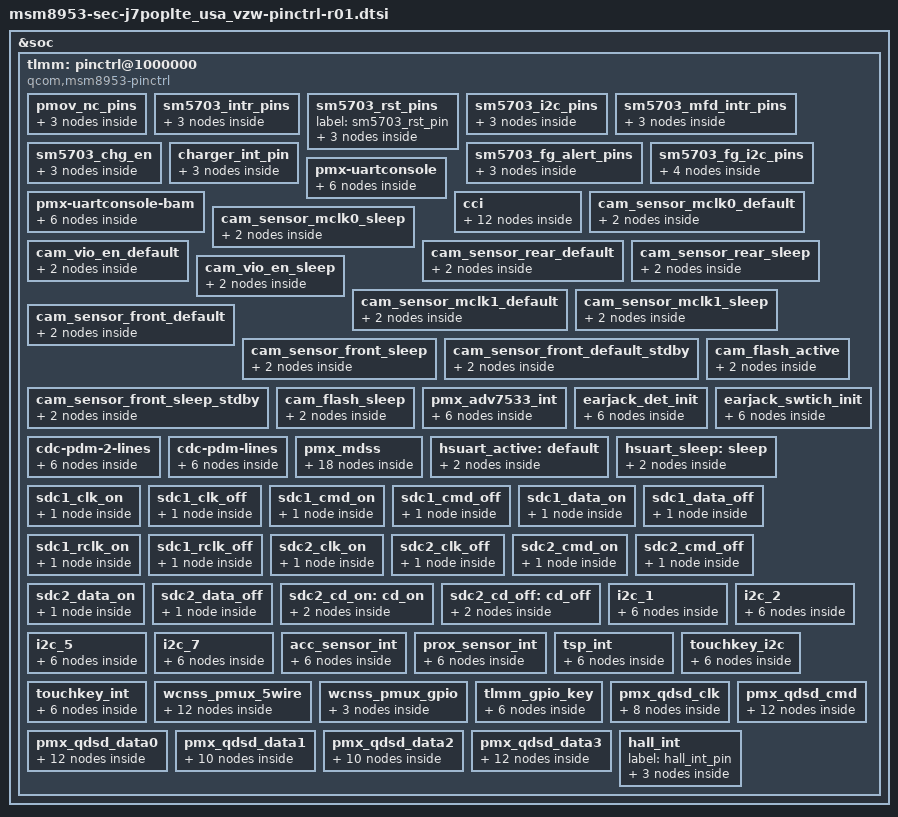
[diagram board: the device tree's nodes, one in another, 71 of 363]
/*
 * Copyright (c) 2015-2016, The Linux Foundation. All rights reserved.
 *
 * This program is free software; you can redistribute it and/or modify
 * it under the terms of the GNU General Public License version 2 and
 * only version 2 as published by the Free Software Foundation.
 *
 * This program is distributed in the hope that it will be useful,
 * but WITHOUT ANY WARRANTY; without even the implied warranty of
 * MERCHANTABILITY or FITNESS FOR A PARTICULAR PURPOSE.  See the
 * GNU General Public License for more details.
 */

&soc {
	tlmm: pinctrl@1000000 {
		compatible = "qcom,msm8953-pinctrl";
		reg = <0x1000000 0x300000>;
		interrupts = <0 208 0>;
		gpio-controller;
		#gpio-cells = <2>;
		interrupt-controller;
		#interrupt-cells = <2>;

		pmov_nc_pins {
			label = "pmov_nc_pins";
			qcom,num-grp-pins = <1>;
			qcom,pin-func = <0>;
			nc_gpio_default: default {
				mux {
					pins = "gpio33", "gpio96";
					function ="gpio";
				};
				config {
					pins = "gpio33", "gpio96";
					drive-strength = <2>; /* 2mA */
					bias-pull-down;
					input-enable;
				};
			};
		};

		sm5703_intr_pins {
			qcom,pin-func = <0>;
			label = "sm5703_gpio_int";
			sm5703_interrupt_default: default {
				mux {
					pins = "gpio63";
					function = "gpio";
				};
				config {
					pins = "gpio63";
					drive-strength = <2>;
					bias-disable;
				};
			};
		};

		sm5703_rst_pins {
			label = "sm5703_rst_pin";
			sm5703_rst_default: default {
				mux {
					pins = "gpio87";
					function = "gpio";
				};
				config {
					pins = "gpio87";
					drive-strength = <2>;
					bias-disable;
					output-high;
				};
			};
		};

		sm5703_i2c_pins {
			sm5703_i2c_default: default {
				mux {
					pins = "gpio98", "gpio99"; /* SDA, SCL */
                        		function = "gpio";
				};
				config {
					pins = "gpio98", "gpio99";
					drive-strength = <2>;
					bias-disable;
				};
			};
		};

		sm5703_mfd_intr_pins {
			sm5703_mfd_interrupt_default: sm5703_mfd_interrupt_default {
				/*default state*/
				mux {
					pins = "gpio61";
					function = "gpio";
				};
				config {
					pins = "gpio61";
					drive-strength = <2>;
					bias-disable; /* No PULL */
				};
			};
		};

		/* Chg_en pin */
		sm5703_chg_en {
			sm5703_chg_en_default: sm5703_chg_en_default {
				/*default state*/
				mux {
					pins = "gpio128";
					function = "gpio";
				};
				config {
					pins = "gpio128";
					drive-strength = <2>;
					bias-disable;
					output-low;
				};
			};
		};

		charger_int_pin {
			qcom,num-grp-pins = <1>;
			qcom,pin-func = <0>;
			label = "charger_int_gpio";
			charger_int_active: charger_int_active {
				mux {
					pins = "gpio61";
					function = "gpio";
				};
				config {
					pins = "gpio61";
					drive-strength = <2>;
					bias-disable;         /* No PULL */
				};
			};
		};

		/* Fuelgauge alert pin */
                sm5703_fg_alert_pins {
			qcom,num-grp-pins = <1>;
			qcom,pin-func = <0>;
			label = "fuel_int_gpio";
			fuel_int_active: fuel_int_active {
				mux {
					pins = "gpio62";
					function = "gpio";
				};
				config {
					pins = "gpio62";
					drive-strength = <2>;
					bias-disable;         /* No PULL */
					input-enable;
				};
			};
		};

		/* Fuelgauge I2C pins */
		sm5703_fg_i2c_pins {
			qcom,num-grp-pins = <2>;
			qcom,pin-func = <0>;
			label = "fg_i2c";

			fg_i2c_active: fg_i2c_active {
				mux {
					pins = "gpio38", "gpio39";
					function = "gpio";
				};
				config {
					pins = "gpio38", "gpio39";
					drive-strength = <2>;	/* 2 MA */
					bias-disable; /* No PULL */
				};
			};

			fg_i2c_sleep: fg_i2c_sleep {
				drive-strength = <2>;	/* 2 MA */
				bias-disable; /* No PULL */
			};
		};

		pmx-uartconsole {
			uart_console_active: uart_console_active {
				mux {
					pins = "gpio4", "gpio5";
					function = "blsp_uart2";
				};

				config {
					pins = "gpio4", "gpio5";
					drive-strength = <2>;
					bias-pull-down;
				};
			};

			uart_console_sleep: uart_console_sleep {
				mux {
					pins = "gpio4", "gpio5";
					function = "blsp_uart2";
				};

				config {
					pins = "gpio4", "gpio5";
					drive-strength = <2>;
					bias-pull-down;
				};
			};

		};

		pmx-uartconsole-bam {
			uart_console_bam_active: uart_console_bam_active {
				mux {
					pins = "gpio4", "gpio5";
					function = "blsp_uart2";
				};

				config {
					pins = "gpio4", "gpio5";
					drive-strength = <16>;
					bias-disable;
				};
			};

			uart_console_bam_sleep: uart_console_bam_sleep {
				mux {
					pins = "gpio4", "gpio5";
					function = "blsp_uart2";
				};

				config {
					pins = "gpio4", "gpio5";
					drive-strength = <2>;
					bias-disable;
				};
			};

		};

		cci {
			cci0_active: cci0_active {
				/* cci0 active state */
				mux {
					/* CLK, DATA */
					pins = "gpio29", "gpio30";
					function = "cci_i2c";
				};

				config {
					pins = "gpio29", "gpio30";
					drive-strength = <2>; /* 2 MA */
					bias-disable; /* No PULL */
				};
			};

			cci0_suspend: cci0_suspend {
				/* cci0 suspended state */
				mux {
					/* CLK, DATA */
					pins = "gpio29", "gpio30";
					function = "gpio";
				};

				config {
					pins = "gpio29", "gpio30";
					drive-strength = <2>; /* 2 MA */
					bias-disable; /* No PULL */
				};
			};

			cci1_active: cci1_active {
				/* cci1 active state */
				mux {
					/* CLK, DATA */
					pins = "gpio31", "gpio32";
					function = "cci_i2c";
				};

				config {
					pins = "gpio31", "gpio32";
					drive-strength = <2>; /* 2 MA */
					bias-disable; /* No PULL */
				};
			};

			cci1_suspend: cci1_suspend {
				/* cci1 suspended state */
				mux {
					/* CLK, DATA */
					pins = "gpio31", "gpio32";
					function = "gpio";
				};

				config {
					pins = "gpio31", "gpio32";
					drive-strength = <2>; /* 2 MA */
					bias-disable; /* No PULL */
				};
			};
		};

		/*sensors */
		cam_sensor_mclk0_default: cam_sensor_mclk0_default {
			/* MCLK0 */
			mux {
				/* CLK, DATA */
				pins = "gpio26";
				function = "cam_mclk";
			};

			config {
				pins = "gpio26";
				bias-disable; /* No PULL */
				drive-strength = <4>; /* 4 MA */
			};
		};

		cam_sensor_mclk0_sleep: cam_sensor_mclk0_sleep {
			/* MCLK0 */
			mux {
				/* CLK, DATA */
				pins = "gpio26";
				function = "gpio";
			};

			config {
				pins = "gpio26";
				bias-pull-down; /* PULL DOWN */
				drive-strength = <4>; /* 4 MA */
				output-low;
			};
		};

		cam_sensor_rear_default: cam_sensor_rear_default {
			/* RESET */
			mux {
				pins = "gpio40";
				function = "gpio";
			};

			config {
				pins = "gpio40";
				bias-pull-down; /* PULL DOWN */
				drive-strength = <2>; /* 2 MA */
				output-low;
			};
		};

		cam_sensor_rear_sleep: cam_sensor_rear_sleep {
			/* RESET */
			mux {
				pins = "gpio40";
				function = "gpio";
			};

			config {
				pins = "gpio40";
				bias-pull-down; /* PULL DOWN */
				drive-strength = <2>; /* 2 MA */
			};
		};

		cam_vio_en_default: cam_vio_en_default {
			/* VIO */
			mux {
				pins = "gpio134";
				function = "gpio";
			};

			config {
				pins = "gpio134";
				bias-pull-down; /* PULL DOWN */
				drive-strength = <2>; /* 2 MA */
				output-low;
			};
		};

		cam_vio_en_sleep: cam_vio_en_sleep {
			/* VDIO */
			mux {
				pins = "gpio134";
				function = "gpio";
			};

			config {
				pins = "gpio134";
				bias-pull-down; /* PULL DOWN */
				drive-strength = <2>; /* 2 MA */
				output-low;
			};
		};

		cam_sensor_mclk1_default: cam_sensor_mclk1_default {
			/* MCLK1 */
			mux {
				/* CLK, DATA */
				pins = "gpio27";
				function = "cam_mclk";
			};

			config {
				pins = "gpio27";
				bias-disable; /* No PULL */
				drive-strength = <4>; /* 4 MA */
			};
		};

		cam_sensor_mclk1_sleep: cam_sensor_mclk1_sleep {
			/* MCLK1 */
			mux {
				/* CLK, DATA */
				pins = "gpio27";
				function = "gpio";
			};

			config {
				pins = "gpio27";
				bias-pull-down; /* PULL DOWN */
				drive-strength = <4>; /* 4 MA */
				output-low;
			};
		};

		cam_sensor_front_default: cam_sensor_front_default {
			/* RESET*/
			mux {
				pins = "gpio129";
				function = "gpio";
			};

			config {
				pins = "gpio129";
				bias-pull-down; /* PULL DOWN */
				output-low;
				drive-strength = <2>; /* 2 MA */
			};
		};

		cam_sensor_front_sleep: cam_sensor_front_sleep {
			/* RESET */
			mux {
				pins = "gpio129";
				function = "gpio";
			};

			config {
				pins = "gpio129";
				bias-disable; /* No PULL */
				drive-strength = <2>; /* 2 MA */
			};
		};

		cam_sensor_front_default_stdby: cam_sensor_front_default_stdby {
			/* STDBY */
			mux {
				pins = "gpio97";
				function = "gpio";
			};

			config {
				pins = "gpio97";
				bias-pull-down; /* PULL DOWN */
				output-low;
				drive-strength = <2>; /* 2 MA */
			};
		};

		cam_sensor_front_sleep_stdby: cam_sensor_front_sleep_stdby {
			/* STDBY */
			mux {
				pins = "gpio97";
				function = "gpio";
			};

			config {
				pins = "gpio97";
				bias-disable; /* No PULL */
				drive-strength = <2>; /* 2 MA */
			};
		};

		cam_flash_active: cam_flash_active {
			/* TORCH, FLASH */
			mux {
				pins = "gpio34", "gpio36";
				function = "gpio";
			};

			config {
				pins = "gpio34", "gpio36";
				bias-pull-down; /* PULL DOWN */
				drive-strength = <2>; /* 2 MA */
				output-low;
			};
		};

		cam_flash_sleep: cam_flash_sleep {
			/* TORCH, FLASH */
			mux {
				pins = "gpio34", "gpio36";
				function = "gpio";
			};

			config {
				pins = "gpio34", "gpio36";
				bias-pull-down; /* PULL DOWN */
				drive-strength = <2>; /* 2 MA */
				output-low;
			};
		};

		pmx_adv7533_int: pmx_adv7533_int {
			adv7533_int_active: adv7533_int_active {
				mux {
					pins = "gpio90";
					function = "gpio";
				};

				config {
					pins = "gpio90";
					drive-strength = <16>;
					bias-disable;
				};
			};

			adv7533_int_suspend: adv7533_int_suspend {
				mux {
					pins = "gpio90";
					function = "gpio";
				};

				config {
					pins = "gpio90";
					drive-strength = <16>;
					bias-disable;
				};
			};

		};

		/* ear jack */
		earjack_det_init: earjack_det_init {
			earjack_det_act: earjack_det_act {
				mux {
					pins = "gpio48";
					function = "gpio";
				};
				config {
					pins = "gpio48";
					drive-strength = <2>;
					bias-disable;
				};
			};
			earjack_det_sus: earjack_det_sus {
				mux {
					pins = "gpio48";
					function = "gpio";
				};
				config {
					pins = "gpio48";
					drive-strength = <2>;
					bias-disable;
				};
			};
		};

		earjack_swtich_init: earjack_swtich_init {
			earjack_switch_act: earjack_switch_act {
				mux {
					pins = "gpio141";
					function = "gpio";
				};
				config {
					pins = "gpio141";
					drive-strength = <2>;
					bias-disable;
				};
			};
			earjack_switch_sus: earjack_switch_sus {
				mux {
					pins = "gpio141";
					function = "gpio";
				};
				config {
					pins = "gpio141";
					drive-strength = <2>;
					bias-disable;
				};
			};
		};

		cdc-pdm-2-lines {
			cdc_pdm_lines_2_act: pdm_lines_2_on {
				mux {
					pins = "gpio70", "gpio71", "gpio72";
					function = "cdc_pdm0";
				};

				config {
					pins = "gpio70", "gpio71", "gpio72";
					drive-strength = <2>;
				};
			};

			cdc_pdm_lines_2_sus: pdm_lines_2_off {
				mux {
					pins = "gpio70", "gpio71", "gpio72";
					function = "cdc_pdm0";
				};

				config {
					pins = "gpio70", "gpio71", "gpio72";
					drive-strength = <2>;
					bias-disable;
				};
			};
		};

		cdc-pdm-lines {
			cdc_pdm_lines_act: pdm_lines_on {
				mux {
					pins = "gpio69", "gpio73", "gpio74";
					function = "cdc_pdm0";
				};

				config {
					pins = "gpio69", "gpio73", "gpio74";
					drive-strength = <2>;
				};
			};
			cdc_pdm_lines_sus: pdm_lines_off {
				mux {
					pins = "gpio69", "gpio73", "gpio74";
					function = "cdc_pdm0";
				};

				config {
					pins = "gpio69", "gpio73", "gpio74";
					drive-strength = <2>;
					bias-disable;
				};
			};
		};

		pmx_mdss: pmx_mdss {
			mdss_dsi_active: mdss_dsi_active {
				mux {
					pins =
						/* LCD */
						"gpio50", "gpio94",
						/* BLIC */
						"gpio41", "gpio22", "gpio23";

					function = "gpio";
				};

				config {
					pins =
						/* LCD */
						"gpio50", "gpio94",
						/* BLIC */
						"gpio41", "gpio22", "gpio23";

					drive-strength = <8>; /* 8 mA */
					bias-pull-down;
				};
			};

			mdss_dsi_suspend: mdss_dsi_suspend {
				mux {
					pins =
						/* LCD */
						"gpio50", "gpio94",
						/* BLIC */
						"gpio41", "gpio22", "gpio23";

					function = "gpio";
				};

				config {
					pins =
						/* LCD */
						"gpio50", "gpio94",
						/* BLIC */
						"gpio41", "gpio22", "gpio23";

					drive-strength = <2>; /* 2 mA */
					bias-pull-down; /* pull down */
				};
			};

			mdss_dsi_esd_active: mdss_dsi_esd_active {
				mux {
					pins =
						/* ESD */
						"gpio13";

					function = "gpio";
				};

				config {
					pins =
						/* ESD */
						"gpio13";

					drive-strength = <8>; /* 8 mA */
					bias-disable;         /* No PULL */
					input-enable;
				};
			};

			mdss_dsi_esd_suspend: mdss_dsi_esd_suspend {
				mux {
					pins =
						/* ESD */
						"gpio13";

					function = "gpio";
				};

				config {
					pins =
						/* ESD */
						"gpio13";

					drive-strength = <2>; /* 2 mA */
					bias-disable;         /* No PULL */
					input-enable;
				};
			};
			mdss_dsi_blic_active: mdss_dsi_blic_active {
				mux {
					pins =
						/* BLIC I2C */
						"gpio14", "gpio15";

					function = "gpio";
				};

				config {
					pins =
						/* BLIC I2C */
						"gpio14", "gpio15";

					drive-strength = <8>; /* 8 mA */
					bias-disable;         /* No PULL */
					input-enable;
				};
			};

			mdss_dsi_blic_suspend: mdss_dsi_blic_suspend {
				mux {
					pins =
						/* BLIC I2C */
						"gpio14", "gpio15";

					function = "gpio";
				};

				config {
					pins =
						/* BLIC I2C */
						"gpio14", "gpio15";

					drive-strength = <2>; /* 2 mA */
					bias-disable;         /* No PULL */
					input-enable;
				};
			};


		};

		hsuart_active: default {
			mux {
				pins = "gpio14", "gpio15";
				function = "blsp_uart4";
			};

			config {
				pins = "gpio14", "gpio15";
				drive-strength = <16>;
				bias-disable;
			};
		};

		hsuart_sleep: sleep {
			mux {
				pins = "gpio14", "gpio15";
				function = "gpio";
			};

			config {
				pins = "gpio14", "gpio15";
				drive-strength = <2>;
				bias-disable;
			};
		};

		/* SDC pin type */
		sdc1_clk_on: sdc1_clk_on {
			config {
				pins = "sdc1_clk";
				bias-disable;		/* NO pull */
				drive-strength = <16>;	/* 16 MA */
			};
		};

		sdc1_clk_off: sdc1_clk_off {
			config {
				pins = "sdc1_clk";
				bias-disable;		/* NO pull */
				drive-strength = <2>;	/* 2 MA */
			};
		};

		sdc1_cmd_on: sdc1_cmd_on {
			config {
				pins = "sdc1_cmd";
				bias-pull-up;		/* pull up */
				drive-strength = <10>;	/* 10 MA */
			};
		};

		sdc1_cmd_off: sdc1_cmd_off {
			config {
				pins = "sdc1_cmd";
				num-grp-pins = <1>;
				bias-pull-up;		/* pull up */
				drive-strength = <2>;	/* 2 MA */
			};
		};

		sdc1_data_on: sdc1_data_on {
			config {
				pins = "sdc1_data";
				bias-pull-up;		/* pull up */
				drive-strength = <10>;	/* 10 MA */
			};
		};

		sdc1_data_off: sdc1_data_off {
			config {
				pins = "sdc1_data";
				bias-pull-up;		/* pull up */
				drive-strength = <2>;	/* 2 MA */
			};
		};

		sdc1_rclk_on: sdc1_rclk_on {
			config {
				pins = "sdc1_rclk";
				bias-pull-down; /* pull down */
			};
		};

		sdc1_rclk_off: sdc1_rclk_off {
			config {
				pins = "sdc1_rclk";
				bias-pull-down; /* pull down */
			};
		};

		sdc2_clk_on: sdc2_clk_on {
			config {
				pins = "sdc2_clk";
				drive-strength = <16>; /* 16 MA */
				bias-disable; /* NO pull */
			};
		};

		sdc2_clk_off: sdc2_clk_off {
			config {
				pins = "sdc2_clk";
				bias-disable; /* NO pull */
				drive-strength = <2>; /* 2 MA */
			};
		};

		sdc2_cmd_on: sdc2_cmd_on {
			config {
				pins = "sdc2_cmd";
				bias-pull-up; /* pull up */
				drive-strength = <8>; /* 8 MA */
			};
		};

		sdc2_cmd_off: sdc2_cmd_off {
			config {
				pins = "sdc2_cmd";
				bias-pull-up; /* pull up */
				drive-strength = <2>; /* 2 MA */
			};
		};

		sdc2_data_on: sdc2_data_on {
			config {
				pins = "sdc2_data";
				bias-pull-up; /* pull up */
				drive-strength = <8>; /* 8 MA */
			};
		};

		sdc2_data_off: sdc2_data_off {
			config {
				pins = "sdc2_data";
				bias-pull-up; /* pull up */
				drive-strength = <2>; /* 2 MA */
			};
		};

		sdc2_cd_on: cd_on {
			mux {
				pins = "gpio133";
				function = "gpio";
			};

			config {
				pins = "gpio133";
				drive-strength = <2>;
				bias-disable;
			};
		};

		sdc2_cd_off: cd_off {
			mux {
				pins = "gpio133";
				function = "gpio";
			};

			config {
				pins = "gpio133";
				drive-strength = <2>;
				bias-disable;
			};
		};

		i2c_1 {
			i2c_1_active: i2c_1_active {
				/* active state */
				mux {
					pins = "gpio2", "gpio3";
					function = "blsp_i2c1";
				};

				config {
					pins = "gpio2", "gpio3";
					drive-strength = <2>;
					bias-disable;
				};
			};

			i2c_1_sleep: i2c_1_sleep {
				/* suspended state */
				mux {
					pins = "gpio2", "gpio3";
					function = "gpio";
				};

				config {
					pins = "gpio2", "gpio3";
					drive-strength = <2>;
					bias-disable;
				};
			};
		};
		
		i2c_2 {
			i2c_2_active: i2c_2_active {
				/* active state */
				mux {
					pins = "gpio6", "gpio7";
					function = "blsp_i2c2";
				};

				config {
					pins = "gpio6", "gpio7";
					drive-strength = <2>;
					bias-disable;
				};
			};

			i2c_2_sleep: i2c_2_sleep {
				/* suspended state */
				mux {
					pins = "gpio6", "gpio7";
					function = "blsp_i2c2";
				};

				config {
					pins = "gpio6", "gpio7";
					drive-strength = <2>;
					bias-disable;
				};
			};
		};

		i2c_5 {
			i2c_5_active: i2c_5_active {
				/* active state */
				mux {
					pins = "gpio18", "gpio19";
					function = "blsp_i2c5";
				};

				config {
					pins = "gpio18", "gpio19";
					drive-strength = <2>;
					bias-disable;
				};
			};

			i2c_5_sleep: i2c_5_sleep {
				/* suspended state */
				mux {
					pins = "gpio18", "gpio19";
					function = "gpio";
				};

				config {
					pins = "gpio18", "gpio19";
					drive-strength = <2>;
					bias-disable;
				};
			};
		};

		i2c_7 {
			i2c_7_active: i2c_7_active {
				/* active state */
				mux {
					pins = "gpio135", "gpio136";
					function = "blsp_i2c7";
				};

				config {
					pins = "gpio135", "gpio136";
					drive-strength = <2>;
					bias-disable;
				};
			};

			i2c_7_suspend: i2c_7_suspend {
				/* suspended state */
				mux {
					pins = "gpio135", "gpio136";
					function = "gpio";
				};

				config {
					pins = "gpio135", "gpio136";
					drive-strength = <2>;
					bias-disable;
				};
			};
		};

		/* SENSOR PIN */
		acc_sensor_int {
			pins = "gpio42";
			qcom,pin-func = <0>;
			qcom,num-grp-pins = <1>;
			label = "acc_sensor_int";
			acc_sensor_int_active: acc_sensor_int_active {
				mux {
					pins = "gpio42";
					function = "gpio";
				};
				config {
					pins = "gpio42";
					drive-strength = <2>;
					bias-disable;
				};
			};
			acc_sensor_int_suspend: acc_sensor_int_suspend {
				mux {
					pins = "gpio42";
					function = "gpio";
				};
				config {
					pins = "gpio42";
					drive-strength = <2>;
					bias-disable;
				};
			};
		};

		prox_sensor_int {
			pins = "gpio43";
			qcom,pin-func = <0>;
			qcom,num-grp-pins = <1>;
			label = "prox_sensor_int";
			prox_sensor_int_active: prox_sensor_int_active {
				mux {
					pins = "gpio43";
					function = "gpio";
				};
				config {
					pins = "gpio43";
					drive-strength = <2>;
					bias-disable;
				};
			};
			prox_sensor_int_suspend: prox_sensor_int_suspend {
				mux {
					pins = "gpio43";
					function = "gpio";
				};
				config {
					pins = "gpio43";
					drive-strength = <2>;
					bias-disable;
				};
			};
		};

		tsp_int {
			pins = "gpio59";
			qcom,num-grp-pins = <1>;
			qcom,pin-func = <0>;
			label = "tsp_int";
			tsp_int_active: tsp_int_active {
				mux {
					pins = "gpio59";
					function = "gpio";
				};
				config {
					pins = "gpio59";
					drive-strength = <2>;
					bias-disable;
				};
			};
			tsp_int_suspend: tsp_int_suspend {
				mux {
					pins = "gpio59";
					function = "gpio";
				};
				config {
					pins = "gpio59";
					drive-strength = <2>;
					bias-disable;
				};
			};
		};

		touchkey_i2c {
			/*qcom,pins = <&gp 16>, <&gp 17>;*/ /* SDA, SCL */
			pins = "gpio16", "gpio17";
			qcom,num-grp-pins = <2>;
			qcom,pin-func = <0>;
			label = "touchkey_i2c";
			touchkey_i2c_active: touchkey_i2c_active {
				mux {
					pins = "gpio16", "gpio17";
					function = "gpio";
				};
				config {
					pins = "gpio16", "gpio17";
					drive-strength = <2>;
					bias-disable;
				};
			};
			touchkey_i2c_suspend: touchkey_i2c_suspend {
				mux {
					pins = "gpio16", "gpio17";
					function = "gpio";
				};
				config {
					pins = "gpio16", "gpio17";
					drive-strength = <2>;
					bias-disable;
				};
			};
		};

		touchkey_int {
			/*qcom,pins = <&gp 60>;*/ /* INTERRUPT */
			pins = "gpio60";
			qcom,num-grp-pins = <1>;
			qcom,pin-func = <0>;
			label = "touchkey_int";
			touchkey_int_active: touchkey_int_active {
				mux {
					pins = "gpio60";
					funtion = "gpio";
				};
				config {
					pins = "gpio60";
					drive-strength = <2>;
					bias-disable;
				};
			};
			touchkey_int_suspend: touchkey_int_suspend {
				mux {
					pins = "gpio60";
					funtion = "gpio";
				};
				config {
					pins = "gpio60";
					drive-strength = <2>;
					bias-disable;
				};
			};
		};

		wcnss_pmux_5wire {
			/* Active configuration of bus pins */
			wcnss_default: wcnss_default {
				wcss_wlan2 {
					pins = "gpio76";
					function = "wcss_wlan2";
				};
				wcss_wlan1 {
					pins = "gpio77";
					function = "wcss_wlan1";
				};
				wcss_wlan0 {
					pins = "gpio78";
					function = "wcss_wlan0";
				};
				wcss_wlan {
					pins = "gpio79", "gpio80";
					function = "wcss_wlan";
				};

				config {
					pins = "gpio76", "gpio77",
						"gpio78", "gpio79",
						"gpio80";
					drive-strength = <6>; /* 6 MA */
					bias-pull-up; /* PULL UP */
				};
			};

			wcnss_sleep: wcnss_sleep {
				wcss_wlan2 {
					pins = "gpio76";
					function = "wcss_wlan2";
				};
				wcss_wlan1 {
					pins = "gpio77";
					function = "wcss_wlan1";
				};
				wcss_wlan0 {
					pins = "gpio78";
					function = "wcss_wlan0";
				};
				wcss_wlan {
					pins = "gpio79", "gpio80";
					function = "wcss_wlan";
				};

				config {
					pins = "gpio76", "gpio77",
						"gpio78", "gpio79",
						"gpio80";
					drive-strength = <2>; /* 2 MA */
					bias-pull-down; /* PULL Down */
				};
			};
		};

		wcnss_pmux_gpio: wcnss_pmux_gpio {
			wcnss_gpio_default: wcnss_gpio_default {
				/* Active configuration of bus pins */
				mux {
					/* Uses general purpose pins */
					pins = "gpio76", "gpio77",
					"gpio78", "gpio79",
					"gpio80";
					function = "gpio";
				};

				config {
					pins = "gpio76", "gpio77",
						"gpio78", "gpio79",
						"gpio80";
					drive-strength = <6>; /* 6 MA */
					bias-pull-up; /* PULL UP */
				};
			};
		};

		tlmm_gpio_key {
			gpio_key_active: gpio_key_active {
				mux {
					pins = "gpio85", "gpio86";
					function = "gpio";
				};

				config {
					pins = "gpio85", "gpio86";
					drive-strength = <2>;
					bias-pull-up;
				};
			};

			gpio_key_suspend: gpio_key_suspend {
				mux {
					pins = "gpio85", "gpio86";
					function = "gpio";
				};

				config {
					pins = "gpio85", "gpio86";
					drive-strength = <2>;
					bias-pull-up;
				};
			};
		};
		pmx_qdsd_clk {
			qdsd_clk_sdcard: clk_sdcard {
				config {
					pins = "qdsd_clk";
					bias-disable;/* NO pull */
					drive-strength = <16>; /* 16 MA */
				};
			};
			qdsd_clk_trace: clk_trace {
				config {
					pins = "qdsd_clk";
					bias-pull-down; /* pull down */
					drive-strength = <2>; /* 2 MA */
				};
			};
			qdsd_clk_swdtrc: clk_swdtrc {
				config {
					pins = "qdsd_clk";
					bias-pull-down; /* pull down */
					drive-strength = <2>; /* 2 MA */
				};
			};
			qdsd_clk_spmi: clk_spmi {
				config {
					pins = "qdsd_clk";
					bias-pull-down; /* pull down */
					drive-strength = <2>; /* 2 MA */
				};
			};
		};

		pmx_qdsd_cmd {
			qdsd_cmd_sdcard: cmd_sdcard {
				config {
					pins = "qdsd_cmd";
					bias-pull-down; /* pull down */
					drive-strength = <8>; /* 8 MA */
				};
			};
			qdsd_cmd_trace: cmd_trace {
				config {
					pins = "qdsd_cmd";
					bias-pull-down; /* pull down */
					drive-strength = <2>; /* 2 MA */
				};
			};
			qdsd_cmd_swduart: cmd_uart {
				config {
					pins = "qdsd_cmd";
					bias-pull-up; /* pull up */
					drive-strength = <2>; /* 2 MA */
				};
			};
			qdsd_cmd_swdtrc: cmd_swdtrc {
				config {
					pins = "qdsd_cmd";
					bias-pull-up; /* pull up */
					drive-strength = <2>; /* 2 MA */
				};
			};
			qdsd_cmd_jtag: cmd_jtag {
				config {
					pins = "qdsd_cmd";
					bias-disable; /* NO pull */
					drive-strength = <8>; /* 8 MA */
				};
			};
			qdsd_cmd_spmi: cmd_spmi {
				config {
					pins = "qdsd_cmd";
					bias-pull-down; /* pull down */
					drive-strength = <10>; /* 10 MA */
				};
			};
		};

		pmx_qdsd_data0 {
			qdsd_data0_sdcard: data0_sdcard {
				config {
					pins = "qdsd_data0";
					bias-pull-down; /* pull down */
					drive-strength = <8>; /* 8 MA */
				};
			};
			qdsd_data0_trace: data0_trace {
				config {
					pins = "qdsd_data0";
					bias-pull-down; /* pull down */
					drive-strength = <8>; /* 8 MA */
				};
			};
			qdsd_data0_swduart: data0_uart {
				config {
					pins = "qdsd_data0";
					bias-pull-down; /* pull down */
					drive-strength = <2>; /* 2 MA */
				};
			};
			qdsd_data0_swdtrc: data0_swdtrc {
				config {
					pins = "qdsd_data0";
					bias-pull-down; /* pull down */
					drive-strength = <2>; /* 2 MA */
				};
			};
			qdsd_data0_jtag: data0_jtag {
				config {
					pins = "qdsd_data0";
					bias-pull-up; /* pull up */
					drive-strength = <2>; /* 2 MA */
				};
			};
			qdsd_data0_spmi: data0_spmi {
				config {
					pins = "qdsd_data0";
					bias-pull-down; /* pull down */
					drive-strength = <2>; /* 2 MA */
				};
			};
		};

		pmx_qdsd_data1 {
			qdsd_data1_sdcard: data1_sdcard {
				config {
					pins = "qdsd_data1";
					bias-pull-down; /* pull down */
					drive-strength = <8>; /* 8 MA */
				};
			};
			qdsd_data1_trace: data1_trace {
				config {
					pins = "qdsd_data1";
					bias-pull-down; /* pull down */
					drive-strength = <8>; /* 8 MA */
				};
			};
			qdsd_data1_swduart: data1_uart {
				config {
					pins = "qdsd_data1";
					bias-pull-down; /* pull down */
					drive-strength = <2>; /* 2 MA */
				};
			};
			qdsd_data1_swdtrc: data1_swdtrc {
				config {
					pins = "qdsd_data1";
					bias-pull-down; /* pull down */
					drive-strength = <2>; /* 2 MA */
				};
			};
			qdsd_data1_jtag: data1_jtag {
				config {
					pins = "qdsd_data1";
					bias-pull-down; /* pull down */
					drive-strength = <2>; /* 2 MA */
				};
			};
		};

		pmx_qdsd_data2 {
			qdsd_data2_sdcard: data2_sdcard {
				config {
					pins = "qdsd_data2";
					bias-pull-down; /* pull down */
					drive-strength = <8>; /* 8 MA */
				};
			};
			qdsd_data2_trace: data2_trace {
				config {
					pins = "qdsd_data2";
					bias-pull-down; /* pull down */
					drive-strength = <8>; /* 8 MA */
				};
			};
			qdsd_data2_swduart: data2_uart {
				config {
					pins = "qdsd_data2";
					bias-pull-down; /* pull down */
					drive-strength = <2>; /* 2 MA */
				};
			};
			qdsd_data2_swdtrc: data2_swdtrc {
				config {
					pins = "qdsd_data2";
					bias-pull-down; /* pull down */
					drive-strength = <2>; /* 2 MA */
				};
			};
			qdsd_data2_jtag: data2_jtag {
				config {
					pins = "qdsd_data2";
					bias-pull-up; /* pull up */
					drive-strength = <8>; /* 8 MA */
				};
			};
		};

		pmx_qdsd_data3 {
			qdsd_data3_sdcard: data3_sdcard {
				config {
					pins = "qdsd_data3";
					bias-pull-down; /* pull down */
					drive-strength = <8>; /* 8 MA */
				};
			};
			qdsd_data3_trace: data3_trace {
				config {
					pins = "qdsd_data3";
					bias-pull-down; /* pull down */
					drive-strength = <8>; /* 8 MA */
				};
			};
			qdsd_data3_swduart: data3_uart {
				config {
					pins = "qdsd_data3";
					bias-pull-up; /* pull up */
					drive-strength = <2>; /* 2 MA */
				};
			};
			qdsd_data3_swdtrc: data3_swdtrc {
				config {
					pins = "qdsd_data3";
					bias-pull-up; /* pull up */
					drive-strength = <2>; /* 2 MA */
				};
			};
			qdsd_data3_jtag: data3_jtag {
				config {
					pins = "qdsd_data3";
					bias-pull-up; /* pull up */
					drive-strength = <2>; /* 2 MA */
				};
			};
			qdsd_data3_spmi: data3_spmi {
				config {
					pins = "qdsd_data3";
					bias-pull-down; /* pull down */
					drive-strength = <8>; /* 8 MA */
				};
			};
		};

		hall_int {
			label = "hall_int_pin";
			hall_int_default: default {
				mux {
					pins = "gpio44";
					function = "gpio";
				};
				config {
					pins = "gpio44";
					drive-strength = <2>;
					bias-disable;
				};
			};
		};
	};
};
